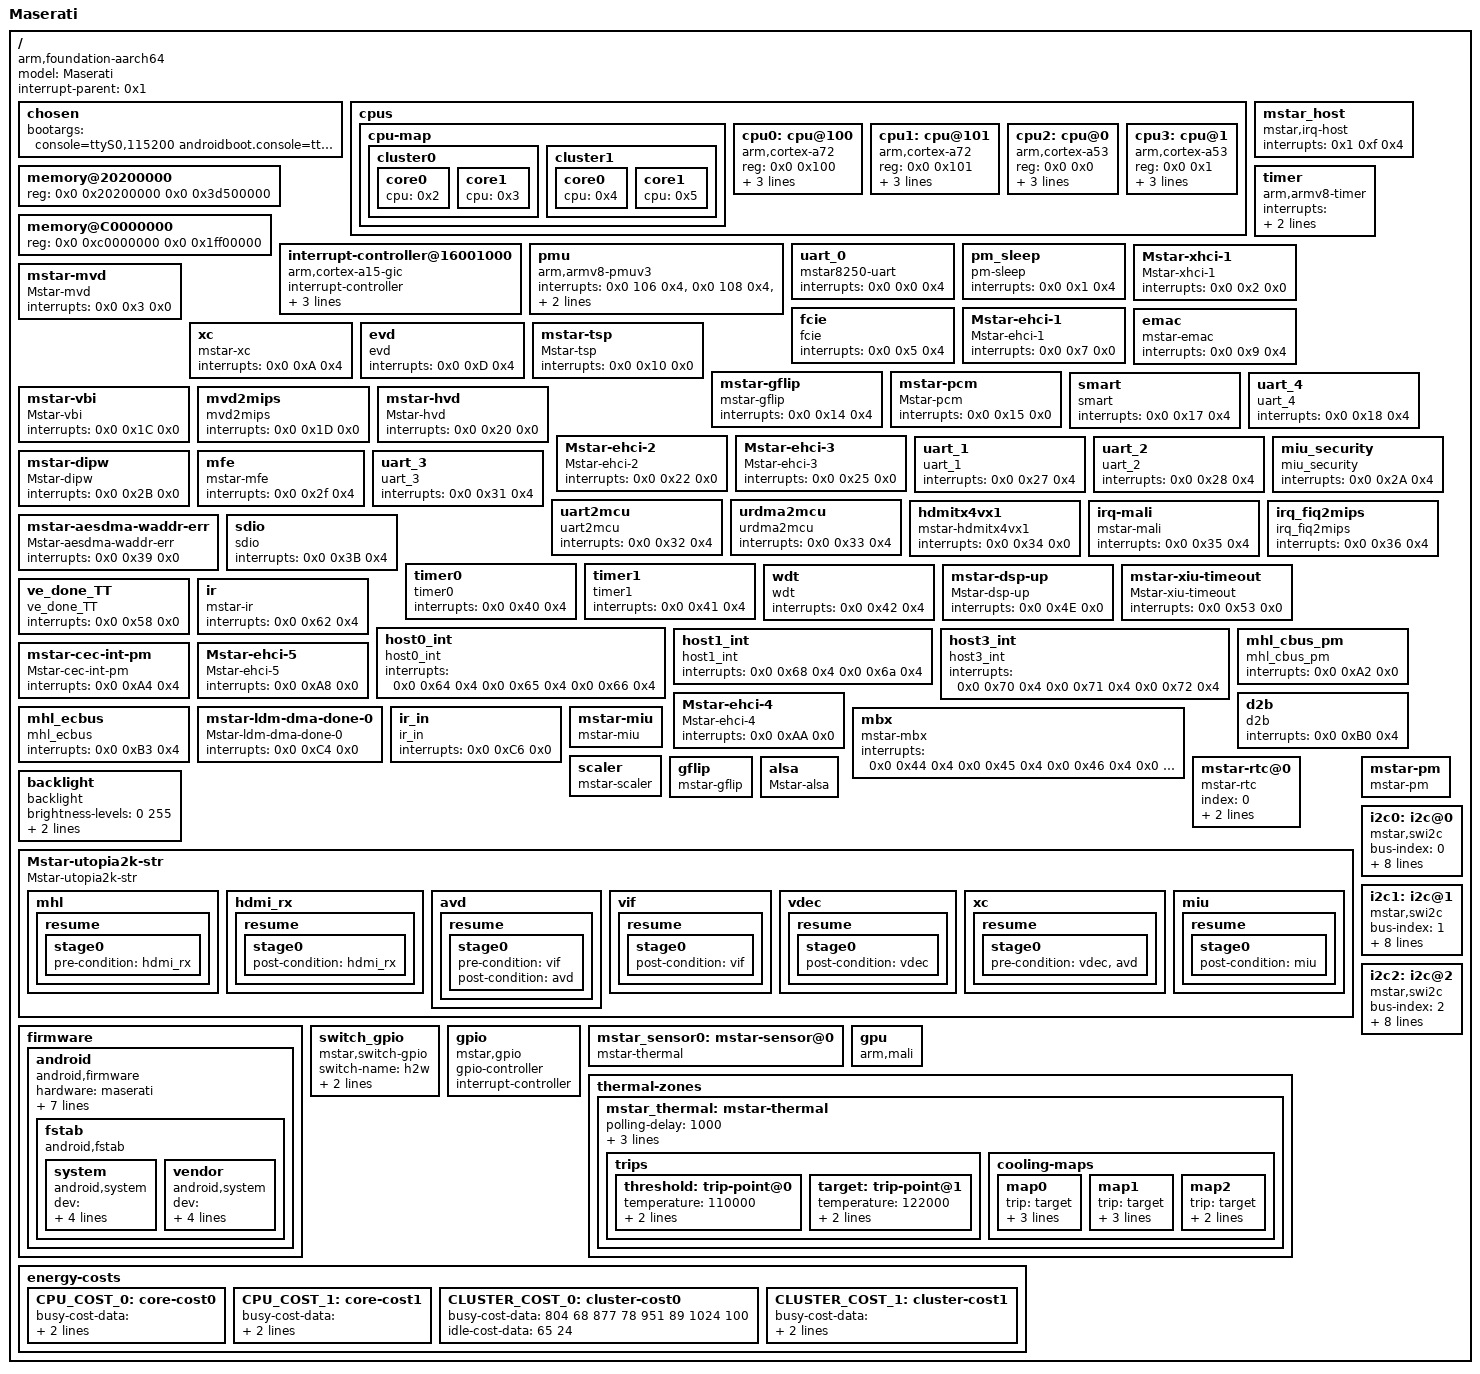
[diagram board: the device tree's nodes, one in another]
#include <dt-bindings/interrupt-controller/arm-gic.h>
#include <dt-bindings/interrupt-controller/irq.h>
#include <dt-bindings/thermal/thermal.h>

/dts-v1/;

/ {
	model = "Maserati";
	compatible = "arm,foundation-aarch64", "arm,maserati";
	interrupt-parent = <0x1>;
	#address-cells = <0x2>;
	#size-cells = <0x2>;

	chosen {
		bootargs = "console=ttyS0,115200 androidboot.console=ttyS0 root=/dev/ram rw rootwait init=/init CORE_DUMP_PATH=/data/core_dump.%%p.gz KDebug=1 delaylogo=true androidboot.selinux=permissive LX_MEM=0x3D500000 LX_MEM2=0xC0000000,0x1FF00000 EMAC_MEM=0x100000 PM51_ADDR=0x20010000 PM51_LEN=0x10000 CMA0=OTHERS,miu=0,hid=23,sz=0x7000000,st=0x11000000 CMA1=VDEC0,miu=0,hid=20,sz=0x3000000,st=0x18000000 CMA2=XC0,miu=0,hid=22,sz=0x6000000,st=0x1b000000 CMA3=OTHERS2,miu=1,hid=24,sz=0xec00000,st=0x0 CMA4=VDEC1,miu=1,hid=19,sz=0x7000000,st=0xec00000 CMA5=RETURN_ENUM,miu=1,hid=25,sz=0x2400000,st=0x15c00000 BOOTLOGO_IN_MBOOT ENV_VAR_OFFSET=0x0 ENV_VAR_SIZE=0x10000 ENV=EMMC SECURITY=ON";
	};

	cpus {
		#address-cells = <0x2>;
		#size-cells = <0x0>;

		cpu-map {

			cluster0: cluster0 {
				#cooling-cells = <0x2>;

				core0 {
					cpu = <0x2>;
				};

				core1 {
					cpu = <0x3>;
				};
			};

			cluster1: cluster1 {
				#cooling-cells = <0x2>;

				core0 {
					cpu = <0x4>;
				};

				core1 {
					cpu = <0x5>;
				};
			};
		};

		cpu0: cpu@100 {
			compatible = "arm,cortex-a72", "arm,armv8";
			reg = <0x0 0x100>;
			device_type = "cpu";
			enable-method = "mstar-spin-table";
			cpu-release-addr = <0x0 0x100510>;
			linux,phandle = <0x4>;
			phandle = <0x4>;
			sched-energy-costs = <&CPU_COST_0 &CLUSTER_COST_0>;
		};

		cpu1: cpu@101 {
			compatible = "arm,cortex-a72", "arm,armv8";
			reg = <0x0 0x101>;
			device_type = "cpu";
			enable-method = "mstar-spin-table";
			cpu-release-addr = <0x0 0x100510>;
			linux,phandle = <0x5>;
			phandle = <0x5>;
			sched-energy-costs = <&CPU_COST_0 &CLUSTER_COST_0>;
		};

		cpu2: cpu@0 {
			compatible = "arm,cortex-a53", "arm,armv8";
			reg = <0x0 0x0>;
			device_type = "cpu";
			enable-method = "mstar-spin-table";
			cpu-release-addr = <0x0 0x100510>;
			linux,phandle = <0x2>;
			phandle = <0x2>;
			sched-energy-costs = <&CPU_COST_1 &CLUSTER_COST_1>;
		};

		cpu3: cpu@1 {
			compatible = "arm,cortex-a53", "arm,armv8";
			reg = <0x0 0x1>;
			device_type = "cpu";
			enable-method = "mstar-spin-table";
			cpu-release-addr = <0x0 0x100510>;
			linux,phandle = <0x3>;
			phandle = <0x3>;
			sched-energy-costs = <&CPU_COST_1 &CLUSTER_COST_1>;
		};
	};

	memory@20200000 {
		device_type = "memory";
		reg = <0x0 0x20200000 0x0 0x3d500000>;
	};

	memory@C0000000 {
		device_type = "memory";
		reg = <0x0 0xc0000000 0x0 0x1ff00000>;
	};

	interrupt-controller@16001000 {
		compatible = "arm,cortex-a15-gic", "arm,cortex-a9-gic";
		#interrupt-cells = <0x3>;
		#address-cells = <0x0>;
		interrupt-controller;
		reg = <0x0 0x16001000 0x0 0x1000 0x0 0x16002000 0x0 0x4000>;
		interrupts = <0x1 0x9 0xf04>;
		linux,phandle = <0x1>;
		phandle = <0x1>;
	};

	mstar_host {
		compatible = "mstar,irq-host";
		interrupts = <0x1 0xf 0x4>;
	};

	timer {
		compatible = "arm,armv8-timer";
		interrupts = <0x1 0xd 0xff01 0x1 0xe 0xff01 0x1 0xb 0xff01 0x1 0xa 0xff01>;
		clock-frequency = <0xb71b00>;
	};

	pmu {
		compatible = "arm,armv8-pmuv3";
		interrupts = <0x0 106 0x4>,
        <0x0 108 0x4>,
        <0x0 115 0x4>,
        <0x0 117 0x4>;
        interrupt-affinity = <&cpu0>,<&cpu1>,<&cpu2>,<&cpu3>;
	};

	uart_0 {
		compatible = "mstar8250-uart";
		interrupts = <0x0 0x0 0x4>;
	};

	pm_sleep {
		compatible = "pm-sleep";
		interrupts = <0x0 0x1 0x4>;
	};

	Mstar-xhci-1 {
		compatible = "Mstar-xhci-1";
		interrupts = <0x0 0x2 0x0>;
	};

	mstar-mvd {
		compatible = "Mstar-mvd";
		interrupts = <0x0 0x3 0x0>;
	};

	fcie {
		compatible = "fcie";
		interrupts = <0x0 0x5 0x4>;
	};

	Mstar-ehci-1 {
		compatible = "Mstar-ehci-1";
		interrupts = <0x0 0x7 0x0>;
	};

	emac {
		compatible = "mstar-emac";
		interrupts = <0x0 0x9 0x4>;
	};

	xc {
		compatible = "mstar-xc";
		interrupts = <0x0 0xA 0x4>;
	};

	evd {
		compatible = "evd";
		interrupts = <0x0 0xD 0x4>;
	};

	mstar-tsp {
		compatible = "Mstar-tsp";
		interrupts = <0x0 0x10 0x0>;
	};

	mstar-gflip {
		compatible = "mstar-gflip";
		interrupts = <0x0 0x14 0x4>;
	};

	mstar-pcm {
		compatible = "Mstar-pcm";
		interrupts = <0x0 0x15 0x0>;
	};

	smart {
		compatible = "smart";
		interrupts = <0x0 0x17 0x4>;
	};

	uart_4 {
		compatible = "uart_4";
		interrupts = <0x0 0x18 0x4>;
	};

	mstar-vbi {
		compatible = "Mstar-vbi";
		interrupts = <0x0 0x1C 0x0>;
	};

	mvd2mips {
		compatible = "mvd2mips";
		interrupts = <0x0 0x1D 0x0>;
	};

	mstar-hvd {
		compatible = "Mstar-hvd";
		interrupts = <0x0 0x20 0x0>;
	};

	Mstar-ehci-2 {
		compatible = "Mstar-ehci-2";
		interrupts = <0x0 0x22 0x0>;
	};

	Mstar-ehci-3 {
		compatible = "Mstar-ehci-3";
		interrupts = <0x0 0x25 0x0>;
	};

	uart_1 {
		compatible = "uart_1";
		interrupts = <0x0 0x27 0x4>;
	};

	uart_2 {
		compatible = "uart_2";
		interrupts = <0x0 0x28 0x4>;
	};

	miu_security {
		compatible = "miu_security";
		interrupts = <0x0 0x2A 0x4>;
	};

	mstar-dipw {
		compatible = "Mstar-dipw";
		interrupts = <0x0 0x2B 0x0>;
	};

	mfe {
		compatible = "mstar-mfe";
		interrupts = <0x0 0x2f 0x4>;
	};

	uart_3 {
		compatible = "uart_3";
		interrupts = <0x0 0x31 0x4>;
	};

	uart2mcu {
		compatible = "uart2mcu";
		interrupts = <0x0 0x32 0x4>;
	};

	urdma2mcu {
		compatible = "urdma2mcu";
		interrupts = <0x0 0x33 0x4>;
	};

	hdmitx4vx1 {
		compatible = "mstar-hdmitx4vx1";
		interrupts = <0x0 0x34 0x0>;
	};

	irq-mali {
		compatible = "mstar-mali";
		interrupts = <0x0 0x35 0x4>;
	};

	irq_fiq2mips {
		compatible = "irq_fiq2mips";
		interrupts = <0x0 0x36 0x4>;
	};

	mstar-aesdma-waddr-err {
		compatible = "Mstar-aesdma-waddr-err";
		interrupts = <0x0 0x39 0x0>;
	};

	sdio {
		compatible = "sdio";
		interrupts = <0x0 0x3B 0x4>;
	};

	timer0 {
		compatible = "timer0";
		interrupts = <0x0 0x40 0x4>;
	};

	timer1 {
		compatible = "timer1";
		interrupts = <0x0 0x41 0x4>;
	};

	wdt {
		compatible = "wdt";
		interrupts = <0x0 0x42 0x4>;
	};

	mstar-dsp-up {
		compatible = "Mstar-dsp-up";
		interrupts = <0x0 0x4E 0x0>;
	};

    mstar-xiu-timeout {
        compatible = "Mstar-xiu-timeout";
        interrupts = <0x0 0x53 0x0>;
    };

	ve_done_TT {
		compatible = "ve_done_TT";
		interrupts = <0x0 0x58 0x0>;
	};

	ir {
		compatible = "mstar-ir";
		interrupts = <0x0 0x62 0x4>;
	};

	host0_int {
		compatible = "host0_int";
		interrupts = <0x0 0x64 0x4  0x0 0x65 0x4  0x0 0x66 0x4>;
	};

	host1_int {
		compatible = "host1_int";
		interrupts = <0x0 0x68 0x4  0x0 0x6a 0x4>;
	};

	host3_int {
		compatible = "host3_int";
		interrupts = <0x0 0x70 0x4  0x0 0x71 0x4  0x0 0x72 0x4>;
	};

	mhl_cbus_pm {
		compatible = "mhl_cbus_pm";
		interrupts = <0x0 0xA2 0x0>;
	};

	mstar-cec-int-pm {
		compatible = "Mstar-cec-int-pm";
		interrupts = <0x0 0xA4 0x4>;
	};

	Mstar-ehci-5 {
		compatible = "Mstar-ehci-5";
		interrupts = <0x0 0xA8 0x0>;
	};

	Mstar-ehci-4 {
		compatible = "Mstar-ehci-4";
		interrupts = <0x0 0xAA 0x0>;
	};

	d2b {
		compatible = "d2b";
		interrupts = <0x0 0xB0 0x4>;
	};

	mhl_ecbus {
		compatible = "mhl_ecbus";
		interrupts = <0x0 0xB3 0x4>;
	};

	mstar-ldm-dma-done-0 {
		compatible = "Mstar-ldm-dma-done-0";
		interrupts = <0x0 0xC4 0x0>;
	};

	ir_in {
		compatible = "ir_in";
		interrupts = <0x0 0xC6 0x0>;
	};
































	mbx {
		compatible = "mstar-mbx";
		interrupts = <0x0 0x44 0x4 0x0 0x45 0x4 0x0 0x46 0x4 0x0 0x47 0x4 0x0 0xC0 0x4 0x0 0xC1 0x4>;
	};

    mstar-miu {
        compatible = "mstar-miu";
    };

	scaler {
		compatible = "mstar-scaler";
	};

	gflip {
		compatible = "mstar-gflip";
	};

	alsa {
		compatible = "Mstar-alsa";
	};

	mstar-rtc@0 {
		compatible = "mstar-rtc";
		index = <0>;
		xtal = <12000000>;
		freq = <1>;
	};

    backlight {
        compatible = "backlight";
        brightness-levels = <0 255>;
        default-brightness-level = <1>;
        bl_ctrl = <12>;
    };

	Mstar-utopia2k-str {
		compatible = "Mstar-utopia2k-str";
		mhl {
		  resume {
		    stage0 {
		      pre-condition = "hdmi_rx";
		    };
		  };
		};
		hdmi_rx {
		  resume {
		    stage0 {
		      post-condition = "hdmi_rx";
		    };
		  };
		};
		avd {
		  resume {
		    stage0 {
		      pre-condition = "vif";
		      post-condition = "avd";
		    };
		  };
		};
		vif {
		  resume {
		    stage0 {
		      post-condition = "vif";
		    };
		  };
		};
		vdec {
		  resume {
		    stage0 {
		      post-condition = "vdec";
		    };
		  };
		};
		xc {
		  resume {
		    stage0 {
		      pre-condition = "vdec","avd";
		    };
		  };
		};
        miu {
          resume {
            stage0 {
              post-condition = "miu";
            };
          };
        };
	};

	mstar-pm {
		compatible = "mstar-pm";
	};

	firmware {
		android {
			compatible = "android,firmware";
			hardware ="maserati";
			revision ="1234";
			Serial   ="0000000000000000";
			Processor ="AArch64 Processor rev 3 (aarch64)";
			serialno ="123456789";
			mode ="123456789";
			baseband ="123456789";
			bootloader ="123456789";
			fstab {
				compatible = "android,fstab";
				system {
					compatible = "android,system";
					dev = "/dev/block/platform/mstar_mci.0/by-name/system";
					type = "ext4";
					mnt_flags = "ro";
					fsmgr_flags = "wait";
				};
				vendor {
					compatible = "android,system";
					dev = "/dev/block/platform/mstar_mci.0/by-name/vendor";
					type = "ext4";
					mnt_flags = "ro";
					fsmgr_flags = "wait";
				};
			};
		};
	};

	switch_gpio {
		compatible = "mstar,switch-gpio";
		switch-name = "h2w";
		switch-gpio = <999>;
		switch-inverse = <0>;
	};

	gpio: gpio{
		compatible = "mstar,gpio";
		gpio-controller;
		#gpio-cells = <1>;
		interrupt-controller;
		#interrupt-cells = <2>; /* cell name GPIO_PAD, trigger-type*/
	};

	/* example of consume a gpio pin with mapped irq
	foo{
		interrupt-parent = <&gpio>;
		interrupts = <0 LEVEL_HIGH>;
	}
	*/
	i2c0: i2c@0 {
		compatible = "mstar,swi2c";
		bus-index = <0>;
		sda-gpio = <54>;
		scl-gpio = <55>;
		speed-khz = <100>;
		def-delay = <100>;
		retries = <5>;
		status = "okay";
		iic-mode = <1>;
		hw-port = <3>;
		pad-mux = <25>;
	};
	i2c1: i2c@1 {
		compatible = "mstar,swi2c";
		bus-index = <1>;
		sda-gpio = <154>;
		scl-gpio = <153>;
		speed-khz = <100>;
		def-delay = <100>;
		retries = <5>;
		status = "okay";
		iic-mode = <0>;
		hw-port = <0>;
		pad-mux = <0>;
	};
	i2c2: i2c@2 {
		compatible = "mstar,swi2c";
		bus-index = <2>;
		sda-gpio = <78>;
		scl-gpio = <77>;
		speed-khz = <100>;
		def-delay = <100>;
		retries = <5>;
		status = "okay";
		iic-mode = <0>;
		hw-port = <0>;
		pad-mux = <0>;
	};

	mstar_sensor0: mstar-sensor@0 {
		compatible = "mstar-thermal";
		#thermal-sensor-cells = <1>;
	};
        gpu: gpu {
                compatible = "arm,mali";
                #cooling-cells = <2>; /* min followed by max */
        };
	thermal-zones {
		mstar_thermal: mstar-thermal {
			polling-delay = <1000>;
			polling-delay-passive = <100>;
			sustainable-power = <10000>;

			thermal-sensors = <&mstar_sensor0 0>;

			trips {
				threshold: trip-point@0 {
					temperature = <110000>;
					hysteresis = <1000>;
					type = "passive";
				};
				target: trip-point@1 {
					temperature = <122000>;
					hysteresis = <1000>;
					type = "passive";
				};
			};

			cooling-maps {
			        map0 {
				     trip = <&target>;
				     contribution = <1024>;
				     cooling-device = <&cluster0 THERMAL_NO_LIMIT THERMAL_NO_LIMIT>;
				};
				map1 {
				     trip = <&target>;
				     contribution = <2048>;
				     cooling-device = <&cluster1 THERMAL_NO_LIMIT THERMAL_NO_LIMIT>;
				};
				map2 {
				     trip = <&target>;
				     contribution = <1024>;
				     cooling-device = <&gpu 0 4>;
				};

			};
		};
	};
    energy-costs {
        CPU_COST_0: core-cost0 {
            busy-cost-data = <
                804 657
                877 769
                951 890
                1024 1022
            >;
            idle-cost-data = <
                15
                0
            >;
        };
        CPU_COST_1: core-cost1 {
            busy-cost-data = <
                397 144
                434 176
                469 213
                506 253
            >;
            idle-cost-data = <
                6
                0
            >;
        };
        CLUSTER_COST_0: cluster-cost0 {
            busy-cost-data = <
                804 68
                877 78
                951 89
                1024 100
            >;
            idle-cost-data = <
                65
                24
            >;
        };
        CLUSTER_COST_1: cluster-cost1 {
            busy-cost-data = <
                397 142
                434 174
                469 210
                506 250
            >;
            idle-cost-data = <
                56
                17
            >;
        };
    };
};
